AUTOSAR XML (schema 4-0-3)
package /ComponentTypes
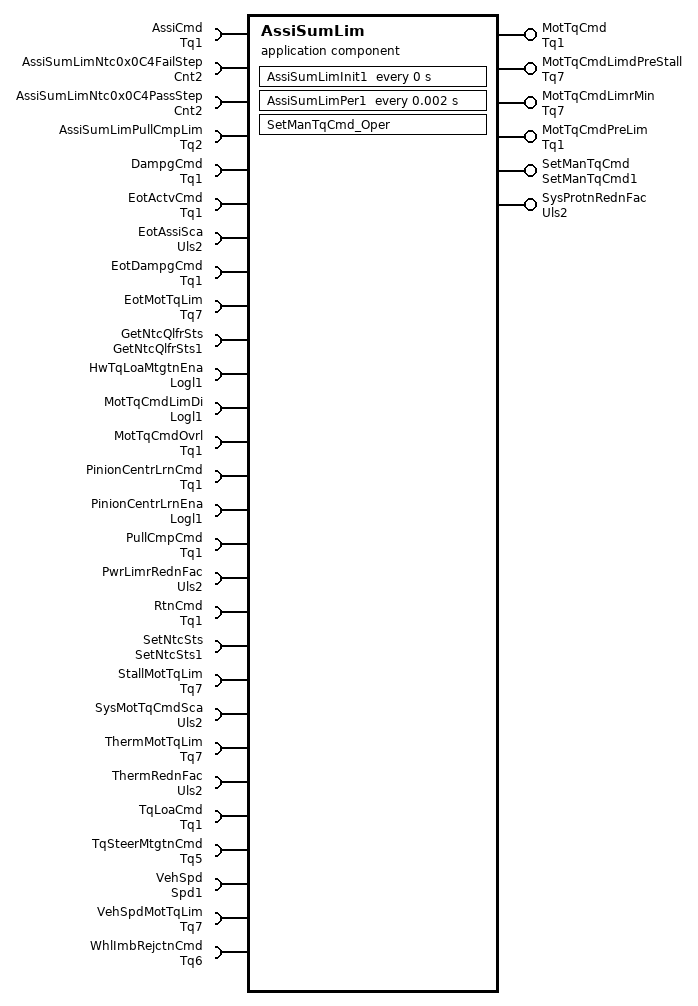
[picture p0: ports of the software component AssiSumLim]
  application sw component type AssiSumLim
    6 x provide port:
      MotTqCmd: nonqueued-sender-com-spec{data-element=Val, init-value=0}, provided-interface=Tq1
      MotTqCmdLimdPreStall: nonqueued-sender-com-spec{data-element=Val, init-value=0}, provided-interface=Tq7
      MotTqCmdLimrMin: nonqueued-sender-com-spec{data-element=Val, init-value=8.8}, provided-interface=Tq7
      MotTqCmdPreLim: nonqueued-sender-com-spec{data-element=Val, init-value=0}, provided-interface=Tq1
      SetManTqCmd: server-com-spec{operation=Oper, queue-length=1}, provided-interface=SetManTqCmd1
      SysProtnRednFac: nonqueued-sender-com-spec{data-element=Val, init-value=0}, provided-interface=Uls2
    28 x require port:
      AssiCmd: nonqueued-receiver-com-spec{data-element=Val, filter=data-filter-type=ALWAYS, init-value=0}, required-interface=Tq1
      AssiSumLimNtc0x0C4FailStep: parameter-require-com-spec{init-value=65535, parameter=Val}, required-interface=Cnt2
      AssiSumLimNtc0x0C4PassStep: parameter-require-com-spec{init-value=65535, parameter=Val}, required-interface=Cnt2
      AssiSumLimPullCmpLim: parameter-require-com-spec{init-value=8.8, parameter=Val}, required-interface=Tq2
      DampgCmd: nonqueued-receiver-com-spec{data-element=Val, filter=data-filter-type=ALWAYS, init-value=0}, required-interface=Tq1
      EotActvCmd: nonqueued-receiver-com-spec{data-element=Val, filter=data-filter-type=ALWAYS, init-value=0}, required-interface=Tq1
      EotAssiSca: nonqueued-receiver-com-spec{data-element=Val, filter=data-filter-type=ALWAYS, init-value=1}, required-interface=Uls2
      EotDampgCmd: nonqueued-receiver-com-spec{data-element=Val, filter=data-filter-type=ALWAYS, init-value=0}, required-interface=Tq1
      EotMotTqLim: nonqueued-receiver-com-spec{data-element=Val, filter=data-filter-type=ALWAYS, init-value=8.8}, required-interface=Tq7
      GetNtcQlfrSts: required-interface=GetNtcQlfrSts1
      HwTqLoaMtgtnEna: nonqueued-receiver-com-spec{data-element=Logl, filter=data-filter-type=ALWAYS, init-value=0}, required-interface=Logl1
      MotTqCmdLimDi: nonqueued-receiver-com-spec{data-element=Logl, filter=data-filter-type=ALWAYS, init-value=0}, required-interface=Logl1
      MotTqCmdOvrl: nonqueued-receiver-com-spec{data-element=Val, filter=data-filter-type=ALWAYS, init-value=0}, required-interface=Tq1
      PinionCentrLrnCmd: nonqueued-receiver-com-spec{data-element=Val, filter=data-filter-type=ALWAYS, init-value=0}, required-interface=Tq1
      PinionCentrLrnEna: nonqueued-receiver-com-spec{data-element=Logl, filter=data-filter-type=ALWAYS, init-value=0}, required-interface=Logl1
      PullCmpCmd: nonqueued-receiver-com-spec{data-element=Val, filter=data-filter-type=ALWAYS, init-value=0}, required-interface=Tq1
      PwrLimrRednFac: nonqueued-receiver-com-spec{data-element=Val, filter=data-filter-type=ALWAYS, init-value=0}, required-interface=Uls2
      RtnCmd: nonqueued-receiver-com-spec{data-element=Val, filter=data-filter-type=ALWAYS, init-value=0}, required-interface=Tq1
      SetNtcSts: required-interface=SetNtcSts1
      StallMotTqLim: nonqueued-receiver-com-spec{data-element=Val, filter=data-filter-type=ALWAYS, init-value=8.8}, required-interface=Tq7
      SysMotTqCmdSca: nonqueued-receiver-com-spec{data-element=Val, filter=data-filter-type=ALWAYS, init-value=1}, required-interface=Uls2
      ThermMotTqLim: nonqueued-receiver-com-spec{data-element=Val, filter=data-filter-type=ALWAYS, init-value=8.8}, required-interface=Tq7
      ThermRednFac: nonqueued-receiver-com-spec{data-element=Val, filter=data-filter-type=ALWAYS, init-value=0}, required-interface=Uls2
      TqLoaCmd: nonqueued-receiver-com-spec{data-element=Val, filter=data-filter-type=ALWAYS, init-value=0}, required-interface=Tq1
      TqSteerMtgtnCmd: nonqueued-receiver-com-spec{data-element=Val, filter=data-filter-type=ALWAYS, init-value=0}, required-interface=Tq5
      VehSpd: nonqueued-receiver-com-spec{data-element=Val, filter=data-filter-type=ALWAYS, init-value=0}, required-interface=Spd1
      VehSpdMotTqLim: nonqueued-receiver-com-spec{data-element=Val, filter=data-filter-type=ALWAYS, init-value=8.8}, required-interface=Tq7
      WhlImbRejctnCmd: nonqueued-receiver-com-spec{data-element=Val, filter=data-filter-type=ALWAYS, init-value=0}, required-interface=Tq6
    behavior AssiSumLim_InternalBehavior: data-type-mapping=Nexteer
      timing event AssiSumLim_InitEvent: start-on-event=AssiSumLimInit1, period=0
      timing event TMT_AssiSumLimPer1: start-on-event=AssiSumLimPer1, period=0.002
      operation invoked event OIT_SetManTqCmd_Oper_SetManTqCmd_Oper: start-on-event=SetManTqCmd_Oper, operation=SetManTqCmd.Oper
      explicit-inter-runnable-variables:
        data ProcdManTqCmd: type=Tq1, init-value=0
        data ProcdManTqCmdEna: type=boolean, init-value=0
      runnable AssiSumLimInit1
        sync call SC_SetNtcSts_Oper: operation=SetNtcSts.Oper, timeout=0
      runnable AssiSumLimPer1
        data-receive-point-by-arguments:
          23 x access:
            REC_AssiCmd_Val: accessed-variable=AssiCmd.Val
            REC_DampgCmd_Val: accessed-variable=DampgCmd.Val
            REC_EotActvCmd_Val: accessed-variable=EotActvCmd.Val
            REC_EotAssiSca_Val: accessed-variable=EotAssiSca.Val
            REC_EotDampgCmd_Val: accessed-variable=EotDampgCmd.Val
            REC_EotMotTqLim_Val: accessed-variable=EotMotTqLim.Val
            REC_HwTqLoaMtgtnEna_Logl: accessed-variable=HwTqLoaMtgtnEna.Logl
            REC_MotTqCmdLimDi_Logl: accessed-variable=MotTqCmdLimDi.Logl
            REC_MotTqCmdOvrl_Val: accessed-variable=MotTqCmdOvrl.Val
            REC_PinionCentrLrnCmd_Val: accessed-variable=PinionCentrLrnCmd.Val
            REC_PinionCentrLrnEna_Logl: accessed-variable=PinionCentrLrnEna.Logl
            REC_PullCmpCmd_Val: accessed-variable=PullCmpCmd.Val
            REC_PwrLimrRednFac_Val: accessed-variable=PwrLimrRednFac.Val
            REC_RtnCmd_Val: accessed-variable=RtnCmd.Val
            REC_StallMotTqLim_Val: accessed-variable=StallMotTqLim.Val
            REC_SysMotTqCmdSca_Val: accessed-variable=SysMotTqCmdSca.Val
            REC_ThermMotTqLim_Val: accessed-variable=ThermMotTqLim.Val
            REC_ThermRednFac_Val: accessed-variable=ThermRednFac.Val
            REC_TqLoaCmd_Val: accessed-variable=TqLoaCmd.Val
            REC_TqSteerMtgtnCmd_Val: accessed-variable=TqSteerMtgtnCmd.Val
            REC_VehSpd_Val: accessed-variable=VehSpd.Val
            REC_VehSpdMotTqLim_Val: accessed-variable=VehSpdMotTqLim.Val
            REC_WhlImbRejctnCmd_Val_1: accessed-variable=WhlImbRejctnCmd.Val
        data-send-points:
          5 x access:
            SEND_MotTqCmd_Val: accessed-variable=MotTqCmd.Val
            SEND_MotTqCmdLimdPreStall_Val: accessed-variable=MotTqCmdLimdPreStall.Val
            SEND_MotTqCmdLimrMin_Val: accessed-variable=MotTqCmdLimrMin.Val
            SEND_MotTqCmdPreLim_Val: accessed-variable=MotTqCmdPreLim.Val
            SEND_SysProtnRednFac_Val: accessed-variable=SysProtnRednFac.Val
        read-local-variables:
          access READ_ProcdManTqCmd: accessed-variable=ProcdManTqCmd
          access READ_ProcdManTqCmdEna: accessed-variable=ProcdManTqCmdEna
        sync call SC_GetNtcQlfrSts_Oper: operation=GetNtcQlfrSts.Oper, timeout=0
        sync call SC_SetNtcSts_Oper: operation=SetNtcSts.Oper, timeout=0
      runnable SetManTqCmd_Oper: can-be-invoked-concurrently=true
        data-receive-point-by-arguments:
          access REC_VehSpd_Val: accessed-variable=VehSpd.Val
        written-local-variables:
          access WRITE_ProcdManTqCmd: accessed-variable=ProcdManTqCmd
          access WRITE_ProcdManTqCmdEna: accessed-variable=ProcdManTqCmdEna
  swc implementation AssiSumLim_Implementation: behavior=AssiSumLim_InternalBehavior
    code-descriptors:
      code Default: artifact-descriptors=autosar-engineering-object={short-label=Default, category=SWSRC}
